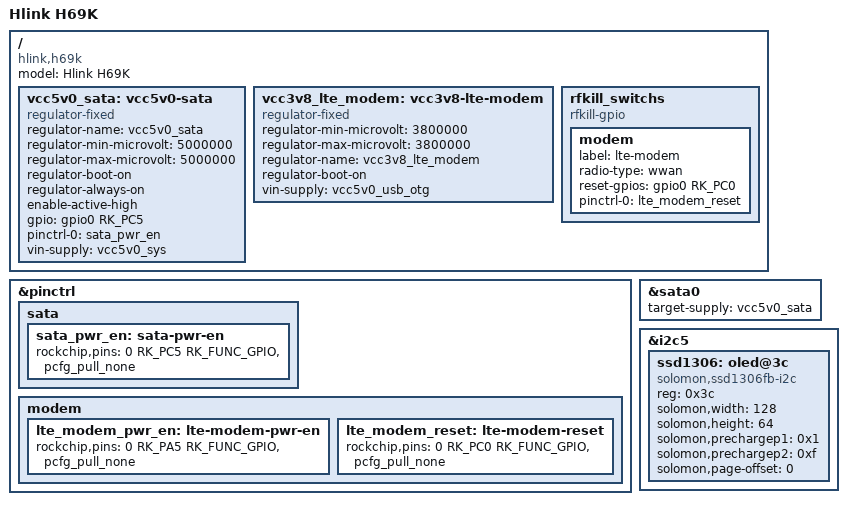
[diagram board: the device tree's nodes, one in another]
// SPDX-License-Identifier: (GPL-2.0+ OR MIT)
// Copyright (c) 2022 AmadeusGhost <amadeus@jmu.edu.cn>
// Copyright (c) 2022 Flippy <flippy@sina.com>

/dts-v1/;

#include "rk3568-hlink-h68k.dts"

/ {
	model = "Hlink H69K";
	compatible = "hlink,h69k", "rockchip,rk3568";

	/* m.2 sata power */
	vcc5v0_sata: vcc5v0-sata {
		compatible = "regulator-fixed";
		regulator-name = "vcc5v0_sata";
		regulator-min-microvolt = <5000000>;
		regulator-max-microvolt = <5000000>;
		regulator-boot-on;
		regulator-always-on;

		enable-active-high;
		gpio = <&gpio0 RK_PC5 GPIO_ACTIVE_HIGH>;
		pinctrl-names = "default";
		pinctrl-0 = <&sata_pwr_en>;
		vin-supply = <&vcc5v0_sys>;
	};

	/* 5g lte modem power */
	vcc3v8_lte_modem: vcc3v8-lte-modem {
		compatible = "regulator-fixed";
		regulator-min-microvolt = <3800000>;
		regulator-max-microvolt = <3800000>;
		regulator-name = "vcc3v8_lte_modem";
		regulator-boot-on;
		vin-supply = <&vcc5v0_usb_otg>;
	};

	rfkill_switchs {
		compatible = "rfkill-gpio";

		modem {
			label = "lte-modem";
			radio-type = "wwan";
			reset-gpios = <&gpio0 RK_PC0 GPIO_ACTIVE_HIGH>;
			pinctrl-names = "default";
			pinctrl-0 = <&lte_modem_reset>;
		};
	};
};

/*
&gic {
	mbi-ranges = <105 20>, <202 56>, <264 56>;
};
*/

&pinctrl {
	sata {
		sata_pwr_en: sata-pwr-en {
			rockchip,pins = <0 RK_PC5 RK_FUNC_GPIO &pcfg_pull_none>;
		};
	};

	modem {
		lte_modem_pwr_en: lte-modem-pwr-en {
			rockchip,pins = <0 RK_PA5 RK_FUNC_GPIO &pcfg_pull_none>;
		};

		lte_modem_reset: lte-modem-reset {
			rockchip,pins = <0 RK_PC0 RK_FUNC_GPIO &pcfg_pull_none>;
		};
	};
};

&sata0 {
	target-supply = <&vcc5v0_sata>;
};

&i2c5 {
	status = "okay";

	ssd1306: oled@3c {
		compatible = "solomon,ssd1306fb-i2c";
		reg = <0x3c>;
		// reset-gpios = <>;
		solomon,width = <128>;
		solomon,height = <64>;
		//solomon,com-lrremap;
		//solomon,com-offset = <32>;
		//solomon,lookup-table = /bits/ 8 <0x3f 0x3f 0x3f 0x3f>;
		solomon,prechargep1 = <0x1>;
		solomon,prechargep2 = <0xf>;
		solomon,page-offset = <0>;
	};
};
